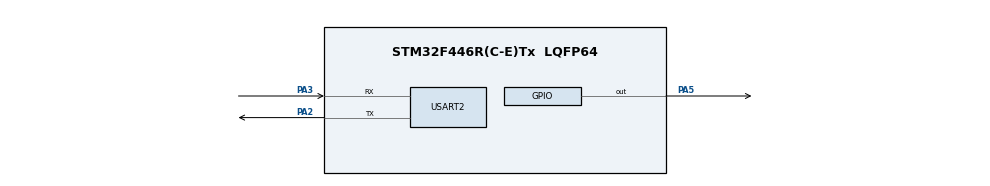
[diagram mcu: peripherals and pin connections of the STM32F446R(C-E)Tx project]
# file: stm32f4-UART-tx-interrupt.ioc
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Mcu.Family=STM32F4
Mcu.Name=STM32F446R(C-E)Tx
Mcu.Package=LQFP64
NVIC.PriorityGroup=NVIC_PRIORITYGROUP_4
NVIC.USART2_IRQn=true\:0\:0\:false\:false\:true\:true\:true
PA13.Mode=Serial_Wire
PA13.Signal=SYS_JTMS-SWDIO
PA14.Mode=Serial_Wire
PA14.Signal=SYS_JTCK-SWCLK
PA2.Mode=Asynchronous
PA2.Signal=USART2_TX
PA3.Mode=Asynchronous
PA3.Signal=USART2_RX
PA5.Signal=GPIO_Output
PC14-OSC32_IN.Mode=LSE-External-Oscillator
PC14-OSC32_IN.Signal=RCC_OSC32_IN
PC15-OSC32_OUT.Mode=LSE-External-Oscillator
PC15-OSC32_OUT.Signal=RCC_OSC32_OUT
PH0-OSC_IN.Mode=HSE-External-Oscillator
PH0-OSC_IN.Signal=RCC_OSC_IN
PH1-OSC_OUT.Mode=HSE-External-Oscillator
PH1-OSC_OUT.Signal=RCC_OSC_OUT
ProjectManager.HeapSize=0x200
ProjectManager.StackSize=0x400
ProjectManager.TargetToolchain=STM32CubeIDE
RCC.CortexFreq_Value=16000000
RCC.USBFreq_Value=96000000
RCC.VCOOutputFreq_Value=192000000
USART2.VirtualMode=VM_ASYNC
board=custom

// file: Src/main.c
/* USER CODE BEGIN Header */
/**
  ******************************************************************************
  * @file           : main.c
  * @brief          : Main program body
  ******************************************************************************
  * @attention
  *
  * <h2><center>&copy; Copyright (c) 2022 STMicroelectronics.
  * All rights reserved.</center></h2>
  *
  * This software component is licensed by ST under BSD 3-Clause license,
  * the "License"; You may not use this file except in compliance with the
  * License. You may obtain a copy of the License at:
  *                        opensource.org/licenses/BSD-3-Clause
  *
  ******************************************************************************
  */
/* USER CODE END Header */

#include "main.h"
#include "usart.h"
#include "gpio.h"

/* USER CODE BEGIN PV */
double value = 1.0;
//char msg[20] = "";
uint8_t  msg[2000];

 void HAL_UART_TxHalfCpltCallback(UART_HandleTypeDef *huart)
{
  HAL_UART_Transmit_IT(&huart2, msg, sizeof(msg));
}

/* USER CODE END PV */

void SystemClock_Config(void);

int main(void)
{

  /* MCU Configuration--------------------------------------------------------*/

  /* Reset of all peripherals, Initializes the Flash interface and the Systick. */
  HAL_Init();

  /* Configure the system clock */
  SystemClock_Config();

  /* Initialize all configured peripherals */
  MX_GPIO_Init();
  MX_USART2_UART_Init();
  /* USER CODE BEGIN 2 */

  for(int i=0; i<2000; i++)
  {
	  msg[i] = 'a';
  }

  HAL_UART_Transmit_IT(&huart2, msg, sizeof(msg));

  /* USER CODE END 2 */

  /* Infinite loop */
  while (1)
  {

    /* USER CODE BEGIN 3 */

	 // sprintf(msg, "%f\r\n", value);		// from the output string msg
	 // HAL_UART_Transmit(&huart2, (uint8_t*) msg, 10, 100);

	  HAL_GPIO_TogglePin(GPIOA, GPIO_PIN_5);
	  HAL_Delay(250);

  }
  /* USER CODE END 3 */
}

void SystemClock_Config(void)
{
  RCC_OscInitTypeDef RCC_OscInitStruct = {0};
  RCC_ClkInitTypeDef RCC_ClkInitStruct = {0};

  /** Configure the main internal regulator output voltage
  */
  __HAL_RCC_PWR_CLK_ENABLE();
  __HAL_PWR_VOLTAGESCALING_CONFIG(PWR_REGULATOR_VOLTAGE_SCALE3);
  /** Initializes the CPU, AHB and APB busses clocks
  */
  RCC_OscInitStruct.OscillatorType = RCC_OSCILLATORTYPE_HSI;
  RCC_OscInitStruct.HSIState = RCC_HSI_ON;
  RCC_OscInitStruct.HSICalibrationValue = RCC_HSICALIBRATION_DEFAULT;
  RCC_OscInitStruct.PLL.PLLState = RCC_PLL_NONE;
  if (HAL_RCC_OscConfig(&RCC_OscInitStruct) != HAL_OK)
  {
    Error_Handler();
  }
  /** Initializes the CPU, AHB and APB busses clocks
  */
  RCC_ClkInitStruct.ClockType = RCC_CLOCKTYPE_HCLK|RCC_CLOCKTYPE_SYSCLK
                              |RCC_CLOCKTYPE_PCLK1|RCC_CLOCKTYPE_PCLK2;
  RCC_ClkInitStruct.SYSCLKSource = RCC_SYSCLKSOURCE_HSI;
  RCC_ClkInitStruct.AHBCLKDivider = RCC_SYSCLK_DIV1;
  RCC_ClkInitStruct.APB1CLKDivider = RCC_HCLK_DIV1;
  RCC_ClkInitStruct.APB2CLKDivider = RCC_HCLK_DIV1;

  if (HAL_RCC_ClockConfig(&RCC_ClkInitStruct, FLASH_LATENCY_0) != HAL_OK)
  {
    Error_Handler();
  }
}

void Error_Handler(void)
{
}

/************************ (C) COPYRIGHT STMicroelectronics *****END OF FILE****/
